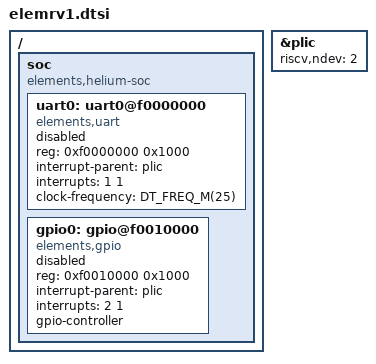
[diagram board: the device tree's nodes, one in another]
/*
 * Copyright (c) 2023 aesc silicon
 *
 * SPDX-License-Identifier: Apache-2.0
 */

#include <elements/hydrogen.dtsi>

/ {
	#address-cells = <1>;
	#size-cells = <1>;

	soc {
		#address-cells = <1>;
		#size-cells = <1>;
		compatible = "elements,helium-soc", "simple-bus";
		ranges;

		uart0: uart0@f0000000 {
			compatible = "elements,uart";
			reg = <0xf0000000 0x1000>;
			interrupt-parent = <&plic>;
			interrupts = <1 1>;
			clock-frequency = <DT_FREQ_M(25)>;
			status = "disabled";
		};

		gpio0: gpio@f0010000 {
			compatible = "elements,gpio";
			reg = <0xf0010000 0x1000>;
			interrupt-parent = <&plic>;
			interrupts = <2 1>;
			gpio-controller;
			#gpio-cells = <2>;
			status = "disabled";
		};
	};
};

&plic {
	riscv,ndev = <2>;
};
